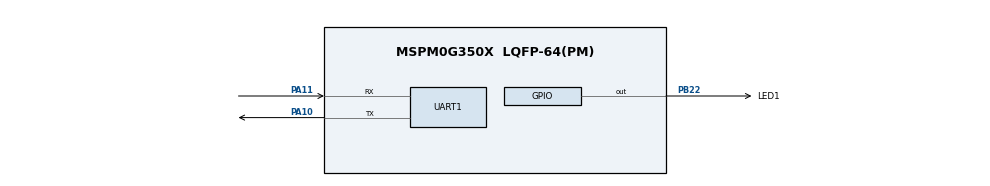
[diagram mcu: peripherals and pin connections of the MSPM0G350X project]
/**
 * @cliArgs --device "MSPM0G350X" --part "Default" --package "LQFP-64(PM)" --product "mspm0_sdk@2.02.00.05"
 * @versions {"tool":"1.21.1+3772"}
 */

/**
 * Import the modules used in this configuration.
 */
const GPIO    = scripting.addModule("/ti/driverlib/GPIO", {}, false);
const GPIO1   = GPIO.addInstance();
const GPIO2   = GPIO.addInstance();
const SYSCTL  = scripting.addModule("/ti/driverlib/SYSCTL");
const SYSTICK = scripting.addModule("/ti/driverlib/SYSTICK");
const UART    = scripting.addModule("/ti/driverlib/UART", {}, false);
const UART1   = UART.addInstance();

/**
 * Write custom configuration values to the imported modules.
 */
GPIO1.$name                              = "LED";
GPIO1.associatedPins.create(1);
GPIO1.associatedPins[0].internalResistor = "PULL_DOWN";
GPIO1.associatedPins[0].assignedPin      = "22";
GPIO1.associatedPins[0].$name            = "LED1";
GPIO1.associatedPins[0].initialValue     = "SET";
GPIO1.associatedPins[0].pin.$assign      = "PB22";

const Board = scripting.addModule("/ti/driverlib/Board", {}, false);

GPIO2.$name                              = "OLED";
GPIO2.port                               = "PORTB";
GPIO2.associatedPins.create(2);
GPIO2.associatedPins[0].$name            = "PIN_SCL";
GPIO2.associatedPins[0].assignedPin      = "9";
GPIO2.associatedPins[0].initialValue     = "SET";
GPIO2.associatedPins[0].internalResistor = "PULL_UP";
GPIO2.associatedPins[1].$name            = "PIN_SDA";
GPIO2.associatedPins[1].initialValue     = "SET";
GPIO2.associatedPins[1].assignedPin      = "8";
GPIO2.associatedPins[1].internalResistor = "PULL_UP";

UART1.$name                    = "UART_0";
UART1.targetBaudRate           = 115200;
UART1.direction                = "TX_RX";
UART1.uartClkSrc               = "MFCLK";
UART1.uartClkDiv               = 1;
UART1.wordLength               = "8_BITS";
UART1.parity                   = "NONE";
UART1.stopBits                 = "ONE";
UART1.flowControl              = "NONE";
UART1.peripheral.$assign       = "UART0";
UART1.peripheral.txPin.$assign = "PA10";
UART1.peripheral.rxPin.$assign = "PA11";

SYSCTL.forceDefaultClkConfig = false;
SYSCTL.MCLKSource            = "HSCLK";
SYSCTL.HSCLKSource           = "SYSPLLCLK0";
SYSCTL.SYSPLLSource          = "SYSOSC";
SYSCTL.SYSPLL_Pdiv           = 2;
SYSCTL.SYSPLL_Qdiv           = 10;
SYSCTL.SYSPLL_CLK0En         = true;
SYSCTL.SYSPLL_CLK0Div        = 0;
SYSCTL.UDIV                  = "2";
SYSCTL.waitState             = "2";

SYSTICK.periodEnable  = true;
SYSTICK.systickEnable = true;
SYSTICK.period        = 80;

/**
 * Pinmux solution for unlocked pins/peripherals. This ensures that minor changes to the automatic solver in a future
 * version of the tool will not impact the pinmux you originally saw.  These lines can be completely deleted in order to
 * re-solve from scratch.
 */
Board.peripheral.$suggestSolution            = "DEBUGSS";
Board.peripheral.swclkPin.$suggestSolution   = "PA20";
Board.peripheral.swdioPin.$suggestSolution   = "PA19";
GPIO2.associatedPins[0].pin.$suggestSolution = "PB9";
GPIO2.associatedPins[1].pin.$suggestSolution = "PB8";
SYSCTL.peripheral.$suggestSolution           = "SYSCTL";
UART1.peripheral.$suggestSolution            = "UART0";
UART1.peripheral.txPin.$suggestSolution      = "PA10";
UART1.peripheral.rxPin.$suggestSolution      = "PA11";
